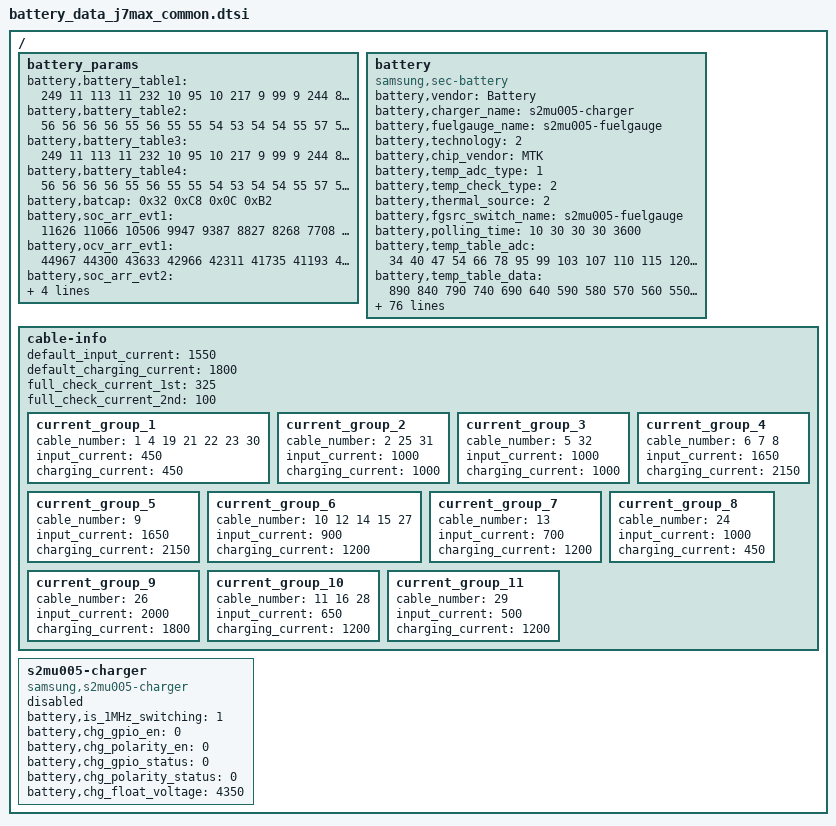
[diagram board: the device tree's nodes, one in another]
/*
 * J7MAX Battery parameters device tree file
 *
 * Copyright (C) 2017 Samsung Electronics, Inc.
 *
 * This program is free software; you can redistribute it and/or
 * modify it under the terms of the GNU General Public License
 * as published by the Free Software Foundation; either version 2
 * of the License, or (at your option) any later version.
 *
 * This program is distributed in the hope that it will be useful,
 * but WITHOUT ANY WARRANTY; without even the implied warranty of
 * MERCHANTABILITY or FITNESS FOR A PARTICULAR PURPOSE.  See the
 * GNU General Public License for more details.
 *
 * You should have received a copy of the GNU General Public License
 * along with this program. If not, see <http://www.gnu.org/licenses/>.
 *
 */

/ {
	battery_params {
			battery,battery_table1 = <
					249 11 113 11 232 10 95 10 217 9
					99 9 244 8 137 8 22 8 188 7
					113 7 12 7 192 6 143 6 105 6
					73 6 47 6 9 6 215 5 148 5
					123 5 73 3 77 9 218 8 104 8
					245 7 130 7 16 7 157 6 43 6
					184 5 69 5 211 4 96 4 238 3
					123 3 8 3 150 2 35 2 177 1
					62 1 203 0 89 0 230 15
					>;

			battery,battery_table2 = <
					56 56 56 56 55 56 55 55 54 53
					54 54 55 57 59 62 66 73 83 101
					131 147
					>;

			battery,battery_table3 = <
					249 11 113 11 232 10 95 10 217 9
					99 9 244 8 137 8 22 8 188 7
					113 7 12 7 192 6 143 6 105 6
					73 6 47 6 9 6 215 5 148 5
					123 5 73 3 77 9 218 8 104 8
					245 7 130 7 16 7 157 6 43 6
					184 5 69 5 211 4 96 4 238 3
					123 3 8 3 150 2 35 2 177 1
					62 1 203 0 89 0 230 15
					>;

			battery,battery_table4 = <
					56 56 56 56 55 56 55 55 54 53
					54 54 55 57 59 62 66 73 83 101
					131 147
					>;

			battery,batcap = <0x32 0xC8 0x0C 0xB2>; /* [0x0F] [0x0E] [0x11] [0x10] */

			battery,soc_arr_evt1 = <11626 11066 10506 9947 9387 8827 8268 7708 7148 6589 6029 5470 4910 4350 3791 3231 2671 2112 1552 992 433 (-127)>;
			battery,ocv_arr_evt1 = <44967 44300 43633 42966 42311 41735 41193 40668 40109 39667 39300 38811 38439 38200 38013 37858 37728 37545 37301 36972 36852 34106>;

			battery,soc_arr_evt2 = <11626 11066 10506 9947 9387 8827 8268 7708 7148 6589 6029 5470 4910 4350 3791 3231 2671 2112 1552 992 433 (-127)>;
			battery,ocv_arr_evt2 = <44967 44300 43633 42966 42311 41735 41193 40668 40109 39667 39300 38811 38439 38200 38013 37858 37728 37545 37301 36972 36852 34106>;

			battery,FG_Accumulative_rate_evt2 = <0xCC 0x7>; /* 0x44 0x45 */
	};

	battery {
		status = "okay";
		compatible = "samsung,sec-battery";

		pinctrl-names = "default";

		battery,vendor = "Battery";
		battery,charger_name = "s2mu005-charger";
		battery,fuelgauge_name = "s2mu005-fuelgauge";
		battery,technology = <2>; /* POWER_SUPPLY_TECHNOLOGY_LION */

		battery,chip_vendor = "MTK";
		battery,temp_adc_type = <1>; /* SEC_BATTERY_ADC_TYPE_AP */

		battery,temp_check_type = <2>; /* SEC_BATTERY_TEMP_CHECK_TEMP */

		battery,thermal_source = <2>; /* SEC_BATTERY_THERMAL_SOURCE_ADC */

		battery,fgsrc_switch_name = "s2mu005-fuelgauge";

		battery,polling_time = <10 30 30 30 3600>;

		battery,temp_table_adc = <
					34 40 47 54 66 78 95 99 103 107
					110 115 120 124 129 136 141 146 151 159
					166 172 180 186 194 201 209 220 227 236
					244 252 262 272 286 294 318 387 461 557
					651 770 872 992 1103 1207 1331 1435 1515
					>;

		battery,temp_table_data = <
					890 840 790 740 690 640 590 580 570 560
					550 540 530 520 510 500 490 480 470 460
					450 440 430 420 410 400 390 380 370 360
					350 340 330 320 310 300 290 240 190 140
					90 40 (-10) (-60) (-110) (-160) (-210) (-260) (-310)
					>;

		battery,adc_check_count = <5>;

		battery,cable_check_type = <4>; /* SEC_BATTERY_CABLE_CHECK_PSY */
		battery,cable_source_type = <1>; /* SEC_BATTERY_CABLE_SOURCE_EXTERNAL */
		battery,polling_type = <1>; /* SEC_BATTERY_MONITOR_ALARM */
		battery,monitor_initial_count = <0>;

		battery,battery_check_type = <0>; /* SEC_BATTERY_CHECK_NONE */
		battery,check_count = <0>;
		battery,check_adc_max = <1440>;
		battery,check_adc_min = <0>;

		battery,ovp_uvlo_check_type = <3>; /* SEC_BATTERY_OVP_UVLO_CHGPOLLING */

		battery,temp_check_count = <1>;
		battery,temp_highlimit_threshold_event = <800>;
		battery,temp_highlimit_recovery_event = <750>;
		battery,temp_high_threshold_event = <500>;
		battery,temp_high_recovery_event = <450>;
		battery,temp_low_threshold_event = <0>;
		battery,temp_low_recovery_event = <50>;
		battery,temp_highlimit_threshold_normal = <800>;
		battery,temp_highlimit_recovery_normal = <750>;
		battery,temp_high_threshold_normal = <500>;
		battery,temp_high_recovery_normal = <450>;
		battery,temp_low_threshold_normal = <0>;
		battery,temp_low_recovery_normal = <50>;
		battery,temp_highlimit_threshold_lpm = <800>;
		battery,temp_highlimit_recovery_lpm = <750>;
		battery,temp_high_threshold_lpm = <500>;
		battery,temp_high_recovery_lpm = <450>;
		battery,temp_low_threshold_lpm = <0>;
		battery,temp_low_recovery_lpm = <50>;
		battery,wpc_high_threshold_normal = <450>;
		battery,wpc_high_recovery_normal = <400>;
		battery,wpc_low_threshold_normal = <0>;
		battery,wpc_low_recovery_normal = <50>;
		battery,full_check_type = <2>; /* SEC_BATTERY_FULLCHARGED_FG_CURRENT */
		battery,full_check_type_2nd = <2>; /* SEC_BATTERY_FULLCHARGED_FG_CURRENT */
		battery,full_check_count = <1>;
		battery,chg_gpio_full_check = <0>;
		battery,chg_polarity_full_check = <1>;

		/* SEC_BATTERY_FULL_CONDITION_SOC |
		   SEC_BATTERY_FULL_CONDITION_NOTIMEFULL |
		   SEC_BATTERY_FULL_CONDITION_VCELL */
		battery,full_condition_type = <15>;
		battery,full_condition_soc = <93>;
		battery,full_condition_vcell = <4250>;

		battery,recharge_check_count = <2>;
		battery,recharge_condition_type = <4>; /* SEC_BATTERY_RECHARGE_CONDITION_VCELL */
		battery,recharge_condition_soc = <98>;
		battery,recharge_condition_vcell = <4280>;

		battery,charging_total_time = <14400>;
		battery,hv_charging_total_time = <10800>;
		battery,normal_charging_total_time = <18000>;
		battery,usb_charging_total_time = <36000>;
		battery,recharging_total_time = <5400>;
		battery,charging_reset_time = <0>;

		battery,chg_float_voltage = <4350>;

		battery,swelling_high_temp_block = <410>;
		battery,swelling_high_temp_recov = <390>;
		battery,swelling_low_temp_block_1st = <150>;
		battery,swelling_low_temp_recov_1st = <200>;
		battery,swelling_low_temp_block_2nd = <50>;
		battery,swelling_low_temp_recov_2nd = <100>;

		battery,swelling_low_temp_current = <750>;	/* 0.3C */
		battery,swelling_low_temp_topoff = <165>;	/* 0.05C */
		battery,swelling_high_temp_current = <1150>;	/* 0.45C */
		battery,swelling_high_temp_topoff = <165>;	/* 0.05C */
		battery,swelling_wc_high_temp_current = <750>;	/* 0.3C */
		battery,swelling_wc_low_temp_current = <750>;	/* 0.3C */

		battery,swelling_drop_float_voltage = <4150>;
		battery,swelling_high_rechg_voltage = <4000>;
		battery,swelling_low_rechg_voltage = <4000>;

		battery,siop_event_check_type = <1>;
		battery,siop_call_cv_current = <330>;
		battery,siop_call_cc_current = <330>;

		battery,siop_input_limit_current = <1200>;
		battery,siop_charging_limit_current = <1000>;

		battery,standard_curr = <1602>; /* TA standard current or AFC current */
		battery,expired_time = <18000>;
		battery,recharging_expired_time = <5400>;

		/* S2MU005 specific error rate calculation (max positive): Float Voltage * (BUCK VSYS sensing, 5%) * (FG ADC, 0.5%)*/
		/* S2MU005 specific error rate calculation (max positive): Float Voltage * 1.05 * 1.005*/
		battery,cisd_max_voltage_thr = <4590>; /* battery ovp detection voltage */
	};

/* sec_battery_cable
 *   0	UNKNOWN,
 *   1	NONE,
 *   2	PREPARE_TA,
 *   3	TA,
 *   4	USB,
 *   5	USB_CDP,
 *   6	9V_TA,
 *   7	9V_ERR,
 *   8	9V_UNKNOWN,
 *   9	12V_TA,
 *  10	WIRELESS,
 *  11	HV_WIRELESS,
 *  12	PMA_WIRELESS,
 *  13	WIRELESS_PACK,
 *  14	WIRELESS_PACK_TA,
 *  15	WIRELESS_STAND,
 *  16	WIRELESS_HV_STAND,
 *  17	QC20,
 *  18	QC30,
 *  19	PDIC,
 *  20	UARTOFF,
 *  21	OTG,
 *  22	LAN_HUB,
 *  23	POWER_SHARING,
 *  24	HMT_CONNECTED,
 *  25	HMT_CHARGE,
 *  26	HV_TA_CHG_LIMIT,
 *  27	WIRELESS_VEHICLE,
 *  28	WIRELESS_HV_VEHICLE,
 *  29	PREPARE_WIRELESS_HV,
 *  30	TIMEOUT,
 *  31	SMART_OTG,
 *  32	SMART_NOTG,
 *  33	CABLE_MAX,
*/
	cable-info {
		default_input_current = <1550>;
		default_charging_current = <1800>;
		full_check_current_1st = <325>;
		full_check_current_2nd = <100>;

		current_group_1 {
			cable_number = <1 4 19 21 22 23 30>;
			input_current = <450>;
			charging_current = <450>;
		};
		current_group_2 {
			cable_number = <2 25 31>;
			input_current = <1000>;
			charging_current = <1000>;
		};
		current_group_3 {
			cable_number = <5 32>;
			input_current = <1000>;
			charging_current = <1000>;
		};
		current_group_4 {
			cable_number = <6 7 8>;
			input_current = <1650>;
			charging_current = <2150>;
		};
		current_group_5 {
			cable_number = <9>;
			input_current = <1650>;
			charging_current = <2150>;
		};
		current_group_6 {
			cable_number = <10 12 14 15 27>;
			input_current = <900>;
			charging_current = <1200>;
		};
		current_group_7 {
			cable_number = <13>;
			input_current = <700>;
			charging_current = <1200>;
		};
		current_group_8 {
			cable_number = <24>;
			input_current = <1000>;
			charging_current = <450>;
		};
		current_group_9 {
			cable_number = <26>;
			input_current = <2000>;
			charging_current = <1800>;
		};
		current_group_10 {
			cable_number = <11 16 28>;
			input_current = <650>;
			charging_current = <1200>;
		};
		current_group_11 {
			cable_number = <29>;
			input_current = <500>;
			charging_current = <1200>;
		};
	};

	s2mu005-charger {
		status = "disable";
		compatible = "samsung,s2mu005-charger";
		battery,is_1MHz_switching = <1>;
		battery,chg_gpio_en = <0>;
		battery,chg_polarity_en = <0>;
		battery,chg_gpio_status = <0>;
		battery,chg_polarity_status = <0>;
		battery,chg_float_voltage = <4350>;
	};
};
